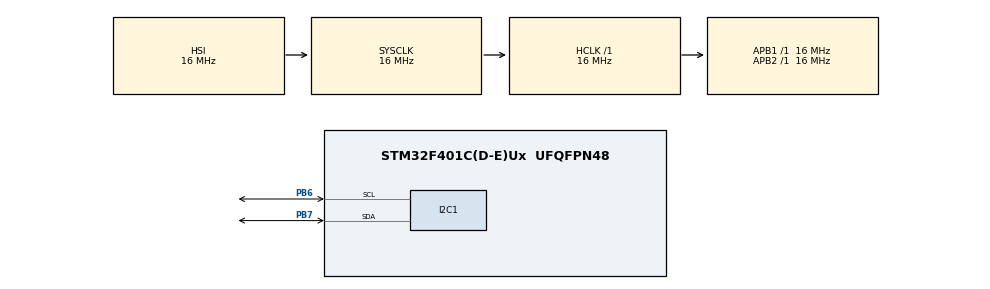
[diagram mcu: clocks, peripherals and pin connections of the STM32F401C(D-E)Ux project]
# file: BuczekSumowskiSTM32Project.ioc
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Mcu.Family=STM32F4
Mcu.Name=STM32F401C(D-E)Ux
Mcu.Package=UFQFPN48
NVIC.PriorityGroup=NVIC_PRIORITYGROUP_4
PB6.Mode=I2C
PB6.Signal=I2C1_SCL
PB7.Mode=I2C
PB7.Signal=I2C1_SDA
ProjectManager.HeapSize=0x200
ProjectManager.StackSize=0x400
ProjectManager.TargetToolchain=STM32CubeIDE
RCC.AHBFreq_Value=16000000
RCC.APB1Freq_Value=16000000
RCC.APB2Freq_Value=16000000
RCC.CortexFreq_Value=16000000
RCC.HSE_VALUE=25000000
RCC.HSI_VALUE=16000000
RCC.LSE_VALUE=32768
RCC.SYSCLKFreq_VALUE=16000000
RCC.VCOOutputFreq_Value=192000000
board=custom

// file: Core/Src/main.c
/* USER CODE BEGIN Header */
/**
  ******************************************************************************
  * @file           : main.c
  * @brief          : Main program body
  ******************************************************************************
  * @attention
  *
  * Copyright (c) 2023 STMicroelectronics.
  * All rights reserved.
  *
  * This software is licensed under terms that can be found in the LICENSE file
  * in the root directory of this software component.
  * If no LICENSE file comes with this software, it is provided AS-IS.
  *
  ******************************************************************************
  */
/* USER CODE END Header */
#include "main.h"

/* USER CODE BEGIN Includes */

#include "vl53l0x_api.h"

/* USER CODE END Includes */

I2C_HandleTypeDef hi2c1;

void SystemClock_Config(void);
static void MX_GPIO_Init(void);
static void MX_I2C1_Init(void);

/* USER CODE BEGIN 0 */

VL53L0X_RangingMeasurementData_t RangingData;
VL53L0X_Dev_t vl53l0x_c; // center module
VL53L0X_DEV Dev = &vl53l0x_c;

uint8_t adress = 0x29;
const uint8_t REG_TEMP = 0x00;

uint16_t mm;

void searchAdresses() {
	/*-[ I2C Bus Scanning ]-*/
	  //HAL_UART_Transmit(&huart1, StartMSG, sizeof(StartMSG), 10000);
	  for(uint8_t i=1; i<128; i++)
	  {
		  uint8_t ret = HAL_I2C_IsDeviceReady(&hi2c1, (uint16_t)(i<<1), 3, 5);
		  if (ret != HAL_OK) /* No ACK Received At That Address */
		  {
			  //HAL_UART_Transmit(&huart1, Space, sizeof(Space), 10000);
		  }
		  else if(ret == HAL_OK)
		  {
			  adress = i;
			  //sprintf(Buffer, "0x%X", i);
			  //AL_UART_Transmit(&huart1, Buffer, sizeof(Buffer), 10000);
		  }
	  }
	  //HAL_UART_Transmit(&huart1, EndMSG, sizeof(EndMSG), 10000);
	/*--[ Scanning Done ]--*/
}

/* USER CODE END 0 */

int main(void)
{
  /* USER CODE BEGIN 1 */

	uint32_t refSpadCount;
	uint8_t isApertureSpads;
	uint8_t VhvSettings;
	uint8_t PhaseCal;

  /* USER CODE END 1 */

  /* MCU Configuration--------------------------------------------------------*/

  /* Reset of all peripherals, Initializes the Flash interface and the Systick. */
  HAL_Init();

  /* Configure the system clock */
  SystemClock_Config();

  /* Initialize all configured peripherals */
  MX_GPIO_Init();
  MX_I2C1_Init();
  /* USER CODE BEGIN 2 */

	//MessageLen = sprintf((char*)Message, "msalamon.pl VL53L0X test\n\r");
	//HAL_UART_Transmit(&huart2, Message, MessageLen, 100);

	Dev->I2cHandle = &hi2c1;
	Dev->I2cDevAddr = adress;

	HAL_GPIO_WritePin(GPIOA, GPIO_PIN_15, GPIO_PIN_RESET); // Disable XSHUT
	HAL_Delay(20);
	HAL_GPIO_WritePin(GPIOA, GPIO_PIN_15, GPIO_PIN_SET); // Enable XSHUT
	HAL_Delay(20);

	//
	// VL53L0X init for Single Measurement
	//

	VL53L0X_WaitDeviceBooted( Dev );
	VL53L0X_DataInit( Dev );
	VL53L0X_StaticInit( Dev );
	VL53L0X_PerformRefCalibration(Dev, &VhvSettings, &PhaseCal);
	VL53L0X_PerformRefSpadManagement(Dev, &refSpadCount, &isApertureSpads);
	VL53L0X_SetDeviceMode(Dev, VL53L0X_DEVICEMODE_SINGLE_RANGING);

	// Enable/Disable Sigma and Signal check
	VL53L0X_SetLimitCheckEnable(Dev, VL53L0X_CHECKENABLE_SIGMA_FINAL_RANGE, 1);
	VL53L0X_SetLimitCheckEnable(Dev, VL53L0X_CHECKENABLE_SIGNAL_RATE_FINAL_RANGE, 1);
	VL53L0X_SetLimitCheckValue(Dev, VL53L0X_CHECKENABLE_SIGNAL_RATE_FINAL_RANGE, (FixPoint1616_t)(0.1*65536));
	VL53L0X_SetLimitCheckValue(Dev, VL53L0X_CHECKENABLE_SIGMA_FINAL_RANGE, (FixPoint1616_t)(60*65536));
	VL53L0X_SetMeasurementTimingBudgetMicroSeconds(Dev, 33000);
	VL53L0X_SetVcselPulsePeriod(Dev, VL53L0X_VCSEL_PERIOD_PRE_RANGE, 18);
	VL53L0X_SetVcselPulsePeriod(Dev, VL53L0X_VCSEL_PERIOD_FINAL_RANGE, 14);

  /* USER CODE END 2 */

  /* Infinite loop */
  /* USER CODE BEGIN WHILE */
  while (1) {

	  VL53L0X_PerformSingleRangingMeasurement(Dev, &RangingData);

	  if(RangingData.RangeStatus == 0) {
		  mm = RangingData.RangeMilliMeter;
		  //HAL_Delay(1000);
		  //MessageLen = sprintf((char*)Message, "Measured distance: %i\n\r", RangingData.RangeMilliMeter);
		  //HAL_UART_Transmit(&huart2, Message, MessageLen, 100);
	  }

    /* USER CODE END WHILE */

  }
}

void SystemClock_Config(void)
{
  RCC_OscInitTypeDef RCC_OscInitStruct = {0};
  RCC_ClkInitTypeDef RCC_ClkInitStruct = {0};

  /** Configure the main internal regulator output voltage
  */
  __HAL_RCC_PWR_CLK_ENABLE();
  __HAL_PWR_VOLTAGESCALING_CONFIG(PWR_REGULATOR_VOLTAGE_SCALE2);

  /** Initializes the RCC Oscillators according to the specified parameters
  * in the RCC_OscInitTypeDef structure.
  */
  RCC_OscInitStruct.OscillatorType = RCC_OSCILLATORTYPE_HSI;
  RCC_OscInitStruct.HSIState = RCC_HSI_ON;
  RCC_OscInitStruct.HSICalibrationValue = RCC_HSICALIBRATION_DEFAULT;
  RCC_OscInitStruct.PLL.PLLState = RCC_PLL_NONE;
  if (HAL_RCC_OscConfig(&RCC_OscInitStruct) != HAL_OK)
  {
    Error_Handler();
  }

  /** Initializes the CPU, AHB and APB buses clocks
  */
  RCC_ClkInitStruct.ClockType = RCC_CLOCKTYPE_HCLK|RCC_CLOCKTYPE_SYSCLK
                              |RCC_CLOCKTYPE_PCLK1|RCC_CLOCKTYPE_PCLK2;
  RCC_ClkInitStruct.SYSCLKSource = RCC_SYSCLKSOURCE_HSI;
  RCC_ClkInitStruct.AHBCLKDivider = RCC_SYSCLK_DIV1;
  RCC_ClkInitStruct.APB1CLKDivider = RCC_HCLK_DIV1;
  RCC_ClkInitStruct.APB2CLKDivider = RCC_HCLK_DIV1;

  if (HAL_RCC_ClockConfig(&RCC_ClkInitStruct, FLASH_LATENCY_0) != HAL_OK)
  {
    Error_Handler();
  }
}

static void MX_I2C1_Init(void)
{

  hi2c1.Instance = I2C1;
  hi2c1.Init.ClockSpeed = 100000;
  hi2c1.Init.DutyCycle = I2C_DUTYCYCLE_2;
  hi2c1.Init.OwnAddress1 = 0;
  hi2c1.Init.AddressingMode = I2C_ADDRESSINGMODE_7BIT;
  hi2c1.Init.DualAddressMode = I2C_DUALADDRESS_DISABLE;
  hi2c1.Init.OwnAddress2 = 0;
  hi2c1.Init.GeneralCallMode = I2C_GENERALCALL_DISABLE;
  hi2c1.Init.NoStretchMode = I2C_NOSTRETCH_DISABLE;
  if (HAL_I2C_Init(&hi2c1) != HAL_OK)
  {
    Error_Handler();
  }

}

static void MX_GPIO_Init(void)
{

  /* GPIO Ports Clock Enable */
  __HAL_RCC_GPIOB_CLK_ENABLE();

}

void Error_Handler(void)
{
  __disable_irq();
  while (1)
  {
  }
}
